AUTOSAR XML (schema 4-0-3)
package /ECU_Abstraction
  4 x client server interface:
    CS_Tire_RPM_Status
      operation get_Tire_RPM
        4 x arg, all with type=sint16, direction=OUT, server-argument-impl-policy=USE-ARGUMENT-TYPE:
          frontleft
          frontright
          backleft
          backright
    CS_AccelPedal_Status
      operation get_AccelPedal_Status
        arg status: type=sint8, direction=OUT, server-argument-impl-policy=USE-ARGUMENT-TYPE
    CS_BrakePedal_Status
      operation get_BrakePedal_Status
        arg status: type=sint8, direction=OUT, server-argument-impl-policy=USE-ARGUMENT-TYPE
    CS_Gear_Mode_Status
      operation get_Gear_Mode
        arg gear_mode: type=sint8, direction=OUT, server-argument-impl-policy=USE-ARGUMENT-TYPE
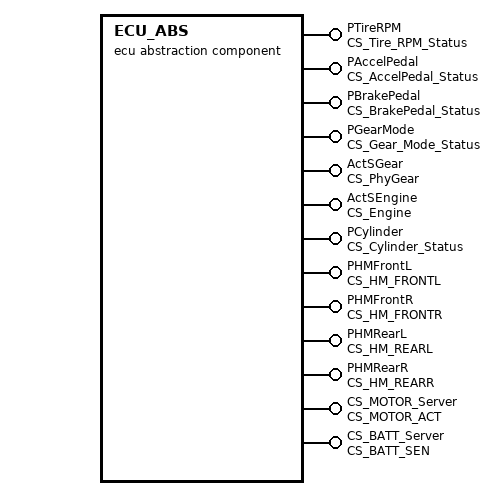
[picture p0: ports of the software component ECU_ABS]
  ecu abstraction sw component type ECU_ABS
    13 x provide port:
      PTireRPM: server-com-spec{operation=get_Tire_RPM, queue-length=10}, provided-interface=CS_Tire_RPM_Status
      PAccelPedal: server-com-spec{operation=get_AccelPedal_Status, queue-length=10}, provided-interface=CS_AccelPedal_Status
      PBrakePedal: server-com-spec{operation=get_BrakePedal_Status, queue-length=10}, provided-interface=CS_BrakePedal_Status
      PGearMode: server-com-spec{operation=get_Gear_Mode, queue-length=10}, provided-interface=CS_Gear_Mode_Status
      ActSGear: server-com-spec{operation=set_phygear, queue-length=10}, provided-interface=CS_PhyGear
      ActSEngine: server-com-spec{operation=set_engine, queue-length=10}, provided-interface=CS_Engine
      PCylinder: server-com-spec{operation=get_cylinder_Status, queue-length=10}, provided-interface=CS_Cylinder_Status
      PHMFrontL: server-com-spec{operation=CS_HM_FRONTL/set_E_op, queue-length=10}, provided-interface=CS_HM_FRONTL
      PHMFrontR: server-com-spec{operation=CS_HM_FRONTR/set_E_op, queue-length=10}, provided-interface=CS_HM_FRONTR
      PHMRearL: server-com-spec{operation=CS_HM_REARL/set_E_op, queue-length=10}, provided-interface=CS_HM_REARL
      PHMRearR: server-com-spec{operation=CS_HM_REARR/set_E_op, queue-length=10}, provided-interface=CS_HM_REARR
      CS_MOTOR_Server: server-com-spec{operation=motor_act_op, queue-length=10}, provided-interface=CS_MOTOR_ACT
      CS_BATT_Server: server-com-spec{operation=batt_sen_op, queue-length=10}, provided-interface=CS_BATT_SEN
    behavior IB_ECU_ABS
      13 x operation invoked event:
        OperationInvokedEvent_0: start-on-event=RE_PTireRPM, operation=PTireRPM.get_Tire_RPM
        OperationInvokedEvent_1: start-on-event=RE_PBrakePedal, operation=PBrakePedal.get_BrakePedal_Status
        OperationInvokedEvent_2: start-on-event=RE_PGearMode, operation=PGearMode.get_Gear_Mode
        OperationInvokedEvent_3: start-on-event=RE_PAccelPedal, operation=PAccelPedal.get_AccelPedal_Status
        OperationInvokedEvent_4: start-on-event=RE_SeverGear, operation=ActSGear.set_phygear
        OperationInvokedEvent_5: start-on-event=RE_PCylinder, operation=PCylinder.get_cylinder_Status
        OperationInvokedEvent_6: start-on-event=RE_SeverEngine, operation=ActSEngine.set_engine
        OperationInvokedEvent_7: start-on-event=RE_PHMRearR, operation=PHMRearR.set_E_op
        OperationInvokedEvent_8: start-on-event=RE_PHMRearL, operation=PHMRearL.set_E_op
        OperationInvokedEvent_9: start-on-event=RE_PHMFrontR, operation=PHMFrontR.set_E_op
        OperationInvokedEvent_10: start-on-event=RE_PHMFrontL, operation=PHMFrontL.set_E_op
        OperationInvokedEvent_11: start-on-event=RE_ECU_ABS_MOTOR, operation=CS_MOTOR_Server.motor_act_op
        OperationInvokedEvent_12: start-on-event=RE_ECU_ABS_BATT, operation=CS_BATT_Server.batt_sen_op
      13 x runnable:
        RE_PTireRPM: symbol=RE_PTireRPM_func
        RE_PAccelPedal: symbol=RE_PAccelPedal_func
        RE_PBrakePedal: symbol=RE_PBrakePedal_func
        RE_PGearMode: symbol=RE_PGearMode_func
        RE_SeverGear: symbol=RE_SeverGear_func
        RE_SeverEngine: symbol=RE_SeverEngine_func
        RE_PCylinder: symbol=RE_PCylinder_func
        RE_PHMFrontL: symbol=RE_PHMFrontL_func
        RE_PHMFrontR: symbol=RE_PHMFrontR_func
        RE_PHMRearL: symbol=RE_PHMRearL_func
        RE_PHMRearR: symbol=RE_PHMRearR_func
        RE_ECU_ABS_MOTOR: symbol=RE_ECU_ABS_MOTOR_func
        RE_ECU_ABS_BATT: symbol=RE_ECU_ABS_BATT_func
  4 x client server interface:
    CS_HM_FRONTL
      operation set_E_op
        arg volt: type=sint16, direction=IN, server-argument-impl-policy=USE-ARGUMENT-TYPE
    CS_HM_FRONTR
      operation set_E_op
        arg volt: type=sint16, direction=IN, server-argument-impl-policy=USE-ARGUMENT-TYPE
    CS_HM_REARL
      operation set_E_op
        arg volt: type=sint16, direction=IN, server-argument-impl-policy=USE-ARGUMENT-TYPE
    CS_HM_REARR
      operation set_E_op
        arg volt: type=sint16, direction=IN, server-argument-impl-policy=USE-ARGUMENT-TYPE
